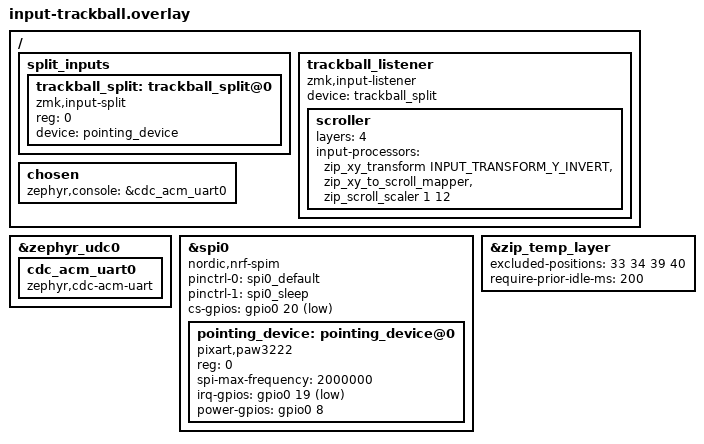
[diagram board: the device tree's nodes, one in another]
#include <input/processors.dtsi>
#include <dt-bindings/zmk/input_transform.h>

&zephyr_udc0 {
    cdc_acm_uart0: cdc_acm_uart0 {
        compatible = "zephyr,cdc-acm-uart";
    };
};

/{
    split_inputs {
        #address-cells = <1>;
        #size-cells = <0>;

        trackball_split: trackball_split@0 {
            compatible = "zmk,input-split";
            reg = <0>;
            device = <&pointing_device>;
        };
    };

    trackball_listener: trackball_listener {
        compatible = "zmk,input-listener";
        device = <&trackball_split>;
        status = "okay";

        scroller {
            layers = <4>;
            input-processors = <
                                &zip_xy_transform INPUT_TRANSFORM_Y_INVERT
                                &zip_xy_to_scroll_mapper
                                &zip_scroll_scaler 1 12
                                >;
        };
    };

    chosen {
        zephyr,console = &cdc_acm_uart0;
    };
};

&spi0 {
    status = "okay";
    compatible = "nordic,nrf-spim";
    pinctrl-0 = <&spi0_default>;
    pinctrl-1 = <&spi0_sleep>;
    pinctrl-names = "default", "sleep";
    cs-gpios = <&gpio0 20 GPIO_ACTIVE_LOW>;

    pointing_device: pointing_device@0 {
        status = "okay";
        compatible = "pixart,paw3222";
        reg = <0>;
        spi-max-frequency = <2000000>;
        irq-gpios = <&gpio0 19 GPIO_ACTIVE_LOW>;
        power-gpios = <&gpio0 8 (GPIO_ACTIVE_HIGH | NRF_GPIO_DRIVE_H0H1)>;
    };
};

&zip_temp_layer {
    excluded-positions = <
        33 // J
        34 // K
        39 // LEFT_SHIFT
        40 // LEFT_CONTROL
    >;
    require-prior-idle-ms = <200>;
};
